# SIM3U164_B register map
File version: 1
CPU: 
Registers are 32-bit, read-write, reset 0x0 unless marked. A register's access mark holds for its fields unless they carry their own. Offsets are from the block's base; [hi:lo] are bit positions.

## DMAXBAR_0
Base 0x40037000
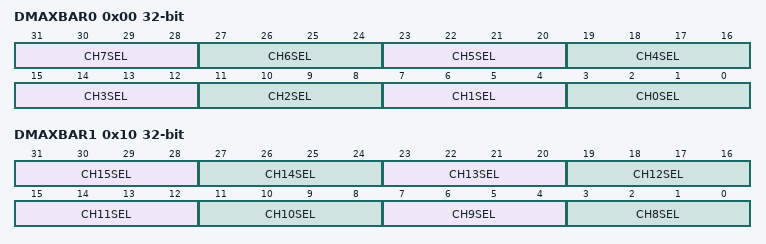
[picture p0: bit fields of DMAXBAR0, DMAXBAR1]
0x00 DMAXBAR0 — Channel 0-7 Trigger Select
  [31:28] CH7SEL — DMA Channel 7 Peripheral Select.
    0=USB0_EP1_IN (Service USB0 EP1 IN data requests.); 1=AES0_XOR (Service AES0 XOR data requests.); 2=SPI1_TX (Service SPI1 TX data requests.); 3=USART0_TX (Service USART0 TX data requests.); 4=DMA0T0_RISE (Service DMAXT0 (PB0.10) rising edge data requests.); 5=DMA0T0_FALL (Service DMAXT0 (PB0.10) falling edge data requests.); 6=DMA0T1_RISE (Service DMAXT1 (PB0.11) rising edge data requests.); 7=DMA0T1_FALL (Service DMAXT1 (PB0.11) falling edge data requests.); 8=TIMER0L (Service TIMER0L overflow data requests.); 9=TIMER1L (Service TIMER1L overflow data requests.); 10=TIMER1H (Service TIMER1H overflow data requests.)
  [27:24] CH6SEL — DMA Channel 6 Peripheral Select.
    0=USB0_EP2_IN (Service USB0 EP2 IN data requests.); 1=AES0_RX (Service AES0 RX data requests.); 2=USART0_RX (Service USART0 RX data requests.); 3=I2C0_RX (Service I2C0 RX data requests.); 4=IDAC0 (Service IDAC0 data requests.); 5=DMA0T0_RISE (Service DMAXT0 (PB0.10) rising edge data requests.); 6=DMA0T0_FALL (Service DMAXT0 (PB0.10) falling edge data requests.); 7=DMA0T1_RISE (Service DMAXT1 (PB0.11) rising edge data requests.); 8=DMA0T1_FALL (Service DMAXT1 (PB0.11) falling edge data requests.); 9=TIMER0H (Service TIMER0H overflow data requests.)
  [23:20] CH5SEL — DMA Channel 5 Peripheral Select.
    0=USB0_EP3_IN (Service USB0 EP3 IN data requests.); 1=AES0_TX (Service AES0 TX data requests.); 2=USART1_TX (Service USART1 TX data requests.); 3=SARADC0 (Service SARADC0 data requests.); 4=I2S0_RX (Service I2S0 RX data requests.); 5=DMA0T0_RISE (Service DMAXT0 (PB0.10) rising edge data requests.); 6=DMA0T0_FALL (Service DMAXT0 (PB0.10) falling edge data requests.); 7=DMA0T1_RISE (Service DMAXT1 (PB0.11) rising edge data requests.); 8=DMA0T1_FALL (Service DMAXT1 (PB0.11) falling edge data requests.)
  [19:16] CH4SEL — DMA Channel 4 Peripheral Select.
    0=USB0_EP4_IN (Service USB0 EP4 IN data requests.); 1=SPI1_TX (Service SPI1 TX data requests.); 2=USART0_TX (Service USART0 TX data requests.); 3=SARADC0 (Service SARADC0 data requests.); 4=I2S0_RX (Service I2S0 RX data requests.); 5=EPCA0_CAPTURE (Service EPCA0 capture data requests.); 6=DMA0T0_RISE (Service DMAXT0 (PB0.10) rising edge data requests.); 7=DMA0T0_FALL (Service DMAXT0 (PB0.10) falling edge data requests.); 8=DMA0T1_RISE (Service DMAXT1 (PB0.11) rising edge data requests.); 9=DMA0T1_FALL (Service DMAXT1 (PB0.11) falling edge data requests.); 10=TIMER0H (Service TIMER0H overflow data requests.)
  [15:12] CH3SEL — DMA Channel 3 Peripheral Select.
    0=USB0_EP1_OUT (Service USB0 EP1 OUT data requests.); 1=SARADC1 (Service SARADC1 data requests.); 2=IDAC0 (Service IDAC0 data requests.); 3=I2S0_TX (Service I2S0 TX data requests.); 4=EPCA0_CAPTURE (Service EPCA0 capture data requests.); 5=DMA0T0_RISE (Service DMAXT0 (PB0.10) rising edge data requests.); 6=DMA0T0_FALL (Service DMAXT0 (PB0.10) falling edge data requests.); 7=DMA0T1_RISE (Service DMAXT1 (PB0.11) rising edge data requests.); 8=DMA0T1_FALL (Service DMAXT1 (PB0.11) falling edge data requests.); 9=TIMER1H (Service TIMER1H overflow data requests.)
  [11:8] CH2SEL — DMA Channel 2 Peripheral Select.
    0=USB0_EP2_OUT (Service USB0 EP2 OUT data requests.); 1=SPI0_TX (Service SPI0 TX data requests.); 2=USART0_TX (Service USART0 TX data requests.); 3=SARADC0 (Service SARADC0 data requests.); 4=IDAC1 (Service IDAC1 data requests.); 5=I2S0_TX (Service I2S0 TX data requests.); 6=EPCA0_CONTROL (Service EPCA0 control data requests.); 7=DMA0T0_RISE (Service DMAXT0 (PB0.10) rising edge data requests.); 8=DMA0T0_FALL (Service DMAXT0 (PB0.10) falling edge data requests.); 9=DMA0T1_RISE (Service DMAXT1 (PB0.11) rising edge data requests.); 10=DMA0T1_FALL (Service DMAXT1 (PB0.11) falling edge data requests.)
  [7:4] CH1SEL — DMA Channel 1 Peripheral Select.
    0=USB0_EP3_OUT (Service USB0 EP3 OUT data requests.); 1=SPI0_RX (Service SPI0 RX data requests.); 2=USART1_RX (Service USART1 RX data requests.); 3=I2C0_RX (Service I2C0 RX data requests.); 4=IDAC1 (Service IDAC1 data requests.); 5=EPCA0_CONTROL (Service EPCA0 control data requests.); 6=DMA0T0_RISE (Service DMAXT0 (PB0.10) rising edge data requests.); 7=DMA0T0_FALL (Service DMAXT0 (PB0.10) falling edge data requests.); 8=DMA0T1_RISE (Service DMAXT1 (PB0.11) rising edge data requests.); 9=DMA0T1_FALL (Service DMAXT1 (PB0.11) falling edge data requests.); 10=TIMER0L (Service TIMER0L overflow data requests.); 11=TIMER1L (Service TIMER1L overflow data requests.); 12=TIMER1H (Service TIMER1H overflow data requests.)
  [3:0] CH0SEL — DMA Channel 0 Peripheral Select.
    0=USB0_EP4_OUT (Service USB0 EP4 OUT data requests.); 1=SPI1_RX (Service SPI1 RX data requests.); 2=USART0_RX (Service USART0 RX data requests.); 3=I2C0_TX (Service I2C0 TX data requests.); 4=DMA0T0_RISE (Service DMAXT0 (PB0.10) rising edge data requests.); 5=DMA0T0_FALL (Service DMAXT0 (PB0.10) falling edge data requests.); 6=DMA0T1_RISE (Service DMAXT1 (PB0.11) rising edge data requests.); 7=DMA0T1_FALL (Service DMAXT1 (PB0.11) falling edge data requests.); 8=TIMER0L (Service TIMER0L overflow data requests.); 9=TIMER0H (Service TIMER0H overflow data requests.); 10=TIMER1L (Service TIMER1L overflow data requests.); 11=TIMER1H (Service TIMER1H overflow data requests.)
0x10 DMAXBAR1 — Channel 8-15 Trigger Select
  [31:28] CH15SEL — DMA Channel 15 Peripheral Select.
    0=USB0_EP1_IN (Service USB0 EP1 IN data requests.); 1=SARADC1 (Service SARADC1 data requests.); 2=IDAC0 (Service IDAC0 data requests.); 3=EPCA0_CONTROL (Service EPCA0 control data requests.); 4=DMA0T0_RISE (Service DMAXT0 (PB0.10) rising edge data requests.); 5=DMA0T0_FALL (Service DMAXT0 (PB0.10) falling edge data requests.); 6=DMA0T1_RISE (Service DMAXT1 (PB0.11) rising edge data requests.); 7=DMA0T1_FALL (Service DMAXT1 (PB0.11) falling edge data requests.); 8=TIMER0H (Service TIMER0H overflow data requests.); 9=TIMER1H (Service TIMER1H overflow data requests.)
  [27:24] CH14SEL — DMA Channel 14 Peripheral Select.
    0=USB0_EP2_IN (Service USB0 EP2 IN data requests.); 1=SPI0_TX (Service SPI0 TX data requests.); 2=USART0_TX (Service USART0 TX data requests.); 3=IDAC0 (Service IDAC0 data requests.); 4=EPCA0_CONTROL (Service EPCA0 control data requests.); 5=DMA0T0_RISE (Service DMAXT0 (PB0.10) rising edge data requests.); 6=DMA0T0_FALL (Service DMAXT0 (PB0.10) falling edge data requests.); 7=DMA0T1_RISE (Service DMAXT1 (PB0.11) rising edge data requests.); 8=DMA0T1_FALL (Service DMAXT1 (PB0.11) falling edge data requests.); 9=TIMER0L (Service TIMER0L overflow data requests.); 10=TIMER1L (Service TIMER1L overflow data requests.)
  [23:20] CH13SEL — DMA Channel 13 Peripheral Select.
    0=USB0_EP3_IN (Service USB0 EP3 IN data requests.); 1=SPI0_RX (Service SPI0 RX data requests.); 2=USART0_RX (Service USART0 RX data requests.); 3=IDAC1 (Service IDAC1 data requests.); 4=I2S0_TX (Service I2S0 TX data requests.); 5=DMA0T0_RISE (Service DMAXT0 (PB0.10) rising edge data requests.); 6=DMA0T0_FALL (Service DMAXT0 (PB0.10) falling edge data requests.); 7=DMA0T1_RISE (Service DMAXT1 (PB0.11) rising edge data requests.); 8=DMA0T1_FALL (Service DMAXT1 (PB0.11) falling edge data requests.); 9=TIMER0H (Service TIMER0H overflow data requests.)
  [19:16] CH12SEL — DMA Channel 12 Peripheral Select.
    0=USB0_EP4_IN (Service USB0 EP4 IN data requests.); 1=AES0_XOR (Service AES0 XOR data requests.); 2=USART1_TX (Service USART1 TX data requests.); 3=SPI1_TX (Service SPI1 TX data requests.); 4=IDAC1 (Service IDAC1 data requests.); 5=I2S0_TX (Service I2S0 TX data requests.); 6=DMA0T0_RISE (Service DMAXT0 (PB0.10) rising edge data requests.); 7=DMA0T0_FALL (Service DMAXT0 (PB0.10) falling edge data requests.); 8=DMA0T1_RISE (Service DMAXT1 (PB0.11) rising edge data requests.); 9=DMA0T1_FALL (Service DMAXT1 (PB0.11) falling edge data requests.); 10=TIMER0L (Service TIMER0L overflow data requests.); 11=TIMER1L (Service TIMER1L overflow data requests.); 12=TIMER1H (Service TIMER1H overflow data requests.)
  [15:12] CH11SEL — DMA Channel 11 Peripheral Select.
    0=USB0_EP1_OUT (Service USB0 EP1 OUT data requests.); 1=AES0_RX (Service AES0 RX data requests.); 2=USART1_RX (Service USART1 RX data requests.); 3=USART0_RX (Service USART0 RX data requests.); 4=I2C0_RX (Service I2C0 RX data requests.); 5=I2S0_RX (Service I2S0 RX data requests.); 6=DMA0T0_RISE (Service DMAXT0 (PB0.10) rising edge data requests.); 7=DMA0T0_FALL (Service DMAXT0 (PB0.10) falling edge data requests.); 8=DMA0T1_RISE (Service DMAXT1 (PB0.11) rising edge data requests.); 9=DMA0T1_FALL (Service DMAXT1 (PB0.11) falling edge data requests.); 10=TIMER0H (Service TIMER0H overflow data requests.)
  [11:8] CH10SEL — DMA Channel 10 Peripheral Select.
    0=USB0_EP2_OUT (Service USB0 EP2 OUT data requests.); 1=AES0_TX (Service AES0 TX data requests.); 2=SARADC1 (Service SARADC1 data requests.); 3=I2S0_RX (Service I2S0 RX data requests.); 4=DMA0T0_RISE (Service DMAXT0 (PB0.10) rising edge data requests.); 5=DMA0T0_FALL (Service DMAXT0 (PB0.10) falling edge data requests.); 6=DMA0T1_RISE (Service DMAXT1 (PB0.11) rising edge data requests.); 7=DMA0T1_FALL (Service DMAXT1 (PB0.11) falling edge data requests.); 8=TIMER1H (Service TIMER1H overflow data requests.)
  [7:4] CH9SEL — DMA Channel 9 Peripheral Select.
    0=USB0_EP3_OUT (Service USB0 EP3 OUT data requests.); 1=USART1_TX (Service USART1 TX data requests.); 2=I2C0_TX (Service I2C0 TX data requests.); 3=EPCA0_CAPTURE (Service EPCA0 capture data requests.); 4=DMA0T0_RISE (Service DMAXT0 (PB0.10) rising edge data requests.); 5=DMA0T0_FALL (Service DMAXT0 (PB0.10) falling edge data requests.); 6=DMA0T1_RISE (Service DMAXT1 (PB0.11) rising edge data requests.); 7=DMA0T1_FALL (Service DMAXT1 (PB0.11) falling edge data requests.); 8=TIMER0H (Service TIMER0H overflow data requests.)
  [3:0] CH8SEL — DMA Channel 8 Peripheral Select.
    0=USB0_EP4_OUT (Service USB0 EP4 OUT data requests.); 1=USART1_RX (Service USART1 RX data requests.); 2=SPI1_RX (Service SPI1 RX data requests.); 3=USART0_RX (Service USART0 RX data requests.); 4=EPCA0_CAPTURE (Service EPCA0 capture data requests.); 5=DMA0T0_RISE (Service DMAXT0 (PB0.10) rising edge data requests.); 6=DMA0T0_FALL (Service DMAXT0 (PB0.10) falling edge data requests.); 7=DMA0T1_RISE (Service DMAXT1 (PB0.11) rising edge data requests.); 8=DMA0T1_FALL (Service DMAXT1 (PB0.11) falling edge data requests.)
